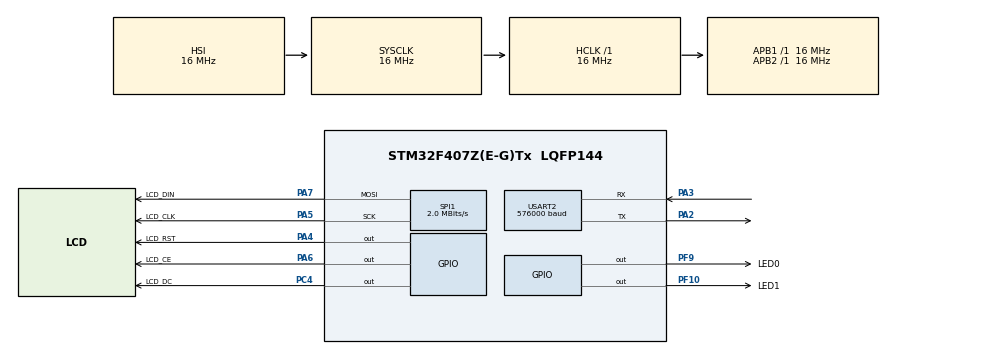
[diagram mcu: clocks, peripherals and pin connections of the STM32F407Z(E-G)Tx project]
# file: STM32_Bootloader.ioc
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Mcu.Family=STM32F4
Mcu.Name=STM32F407Z(E-G)Tx
Mcu.Package=LQFP144
NVIC.PriorityGroup=NVIC_PRIORITYGROUP_4
NVIC.USART2_IRQn=true\:0\:0\:false\:false\:true\:true\:true\:true
PA2.Mode=Asynchronous
PA2.Signal=USART2_TX
PA3.Mode=Asynchronous
PA3.Signal=USART2_RX
PA4.GPIO_Label=LCD_RST
PA4.GPIO_ModeDefaultOutputPP=GPIO_MODE_OUTPUT_PP
PA4.GPIO_PuPd=GPIO_PULLUP
PA4.GPIO_Speed=GPIO_SPEED_FREQ_VERY_HIGH
PA4.PinState=GPIO_PIN_SET
PA4.Signal=GPIO_Output
PA5.GPIO_Label=LCD_CLK
PA5.Mode=TX_Only_Simplex_Unidirect_Master
PA5.Signal=SPI1_SCK
PA6.GPIO_Label=LCD_CE
PA6.GPIO_PuPd=GPIO_PULLUP
PA6.GPIO_Speed=GPIO_SPEED_FREQ_VERY_HIGH
PA6.PinState=GPIO_PIN_SET
PA6.Signal=GPIO_Output
PA7.GPIO_Label=LCD_DIN
PA7.Mode=TX_Only_Simplex_Unidirect_Master
PA7.Signal=SPI1_MOSI
PC4.GPIO_Label=LCD_DC
PC4.GPIO_PuPd=GPIO_PULLUP
PC4.GPIO_Speed=GPIO_SPEED_FREQ_VERY_HIGH
PC4.PinState=GPIO_PIN_SET
PC4.Signal=GPIO_Output
PC6.Signal=SDIO_D6
PF10.GPIO_Label=LED1
PF10.Signal=GPIO_Output
PF9.GPIO_Label=LED0
PF9.Signal=GPIO_Output
ProjectManager.HeapSize=0x200
ProjectManager.StackSize=0x400
ProjectManager.TargetToolchain=STM32CubeIDE
RCC.AHBFreq_Value=16000000
RCC.APB1Freq_Value=16000000
RCC.APB2Freq_Value=16000000
RCC.CortexFreq_Value=16000000
RCC.HSE_VALUE=25000000
RCC.HSI_VALUE=16000000
RCC.LSE_VALUE=32768
RCC.SYSCLKFreq_VALUE=16000000
RCC.VCOOutputFreq_Value=192000000
SPI1.BaudRatePrescaler=SPI_BAUDRATEPRESCALER_8
SPI1.CalculateBaudRate=2.0 MBits/s
SPI1.Direction=SPI_DIRECTION_2LINES
SPI1.Mode=SPI_MODE_MASTER
SPI1.VirtualType=VM_MASTER
USART2.BaudRate=576000
USART2.VirtualMode=VM_ASYNC
board=custom

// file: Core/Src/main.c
/* USER CODE BEGIN Header */
/**
  ******************************************************************************
  * @file           : main.c
  * @brief          : Main program body
  ******************************************************************************
  * @attention
  *
  * Copyright (c) 2024 STMicroelectronics.
  * All rights reserved.
  *
  * This software is licensed under terms that can be found in the LICENSE file
  * in the root directory of this software component.
  * If no LICENSE file comes with this software, it is provided AS-IS.
  *
  ******************************************************************************
  */
/* USER CODE END Header */
#include "main.h"

 SPI_HandleTypeDef hspi1;

UART_HandleTypeDef huart2;

void SystemClock_Config(void);
static void MX_GPIO_Init(void);
static void MX_USART2_UART_Init(void);
static void MX_SPI1_Init(void);
/* USER CODE BEGIN PFP */
extern void initialise_monitor_handles(void);

/* USER CODE END PFP */

int main(void)
{

  /* MCU Configuration--------------------------------------------------------*/

  /* Reset of all peripherals, Initializes the Flash interface and the Systick. */
  HAL_Init();

  /* Configure the system clock */
  SystemClock_Config();

  /* Initialize all configured peripherals */
  MX_GPIO_Init();
  MX_USART2_UART_Init();
  MX_SPI1_Init();
  /* USER CODE BEGIN 2 */

  //initialise_monitor_handles(); // Semi-hosting

  // -- Start LCD Display --
  extern LCD_displayBuffer_t *LCD_displayBuffer01;
  LCD_displayBuffer01 = LCD_SPI_Cmd_initDisplay(LCD_displayBuffer01);

  // -- Start bootloader routine --
  bootloader_init();

  /* USER CODE END 2 */

  /* Infinite loop */
  while (1)
  {

  }
}

void SystemClock_Config(void)
{
  RCC_OscInitTypeDef RCC_OscInitStruct = {0};
  RCC_ClkInitTypeDef RCC_ClkInitStruct = {0};

  /** Configure the main internal regulator output voltage
  */
  __HAL_RCC_PWR_CLK_ENABLE();
  __HAL_PWR_VOLTAGESCALING_CONFIG(PWR_REGULATOR_VOLTAGE_SCALE1);

  /** Initializes the RCC Oscillators according to the specified parameters
  * in the RCC_OscInitTypeDef structure.
  */
  RCC_OscInitStruct.OscillatorType = RCC_OSCILLATORTYPE_HSI;
  RCC_OscInitStruct.HSIState = RCC_HSI_ON;
  RCC_OscInitStruct.HSICalibrationValue = RCC_HSICALIBRATION_DEFAULT;
  RCC_OscInitStruct.PLL.PLLState = RCC_PLL_NONE;
  if (HAL_RCC_OscConfig(&RCC_OscInitStruct) != HAL_OK)
  {
    Error_Handler();
  }

  /** Initializes the CPU, AHB and APB buses clocks
  */
  RCC_ClkInitStruct.ClockType = RCC_CLOCKTYPE_HCLK|RCC_CLOCKTYPE_SYSCLK
                              |RCC_CLOCKTYPE_PCLK1|RCC_CLOCKTYPE_PCLK2;
  RCC_ClkInitStruct.SYSCLKSource = RCC_SYSCLKSOURCE_HSI;
  RCC_ClkInitStruct.AHBCLKDivider = RCC_SYSCLK_DIV1;
  RCC_ClkInitStruct.APB1CLKDivider = RCC_HCLK_DIV1;
  RCC_ClkInitStruct.APB2CLKDivider = RCC_HCLK_DIV1;

  if (HAL_RCC_ClockConfig(&RCC_ClkInitStruct, FLASH_LATENCY_0) != HAL_OK)
  {
    Error_Handler();
  }
}

static void MX_SPI1_Init(void)
{

  /* SPI1 parameter configuration*/
  hspi1.Instance = SPI1;
  hspi1.Init.Mode = SPI_MODE_MASTER;
  hspi1.Init.Direction = SPI_DIRECTION_2LINES;
  hspi1.Init.DataSize = SPI_DATASIZE_8BIT;
  hspi1.Init.CLKPolarity = SPI_POLARITY_LOW;
  hspi1.Init.CLKPhase = SPI_PHASE_1EDGE;
  hspi1.Init.NSS = SPI_NSS_SOFT;
  hspi1.Init.BaudRatePrescaler = SPI_BAUDRATEPRESCALER_8;
  hspi1.Init.FirstBit = SPI_FIRSTBIT_MSB;
  hspi1.Init.TIMode = SPI_TIMODE_DISABLE;
  hspi1.Init.CRCCalculation = SPI_CRCCALCULATION_DISABLE;
  hspi1.Init.CRCPolynomial = 10;
  if (HAL_SPI_Init(&hspi1) != HAL_OK)
  {
    Error_Handler();
  }

}

static void MX_USART2_UART_Init(void)
{

  huart2.Instance = USART2;
  huart2.Init.BaudRate = 576000;
  huart2.Init.WordLength = UART_WORDLENGTH_8B;
  huart2.Init.StopBits = UART_STOPBITS_1;
  huart2.Init.Parity = UART_PARITY_NONE;
  huart2.Init.Mode = UART_MODE_TX_RX;
  huart2.Init.HwFlowCtl = UART_HWCONTROL_NONE;
  huart2.Init.OverSampling = UART_OVERSAMPLING_16;
  if (HAL_UART_Init(&huart2) != HAL_OK)
  {
    Error_Handler();
  }

}

static void MX_GPIO_Init(void)
{
  GPIO_InitTypeDef GPIO_InitStruct = {0};

  /* GPIO Ports Clock Enable */
  __HAL_RCC_GPIOF_CLK_ENABLE();
  __HAL_RCC_GPIOA_CLK_ENABLE();
  __HAL_RCC_GPIOC_CLK_ENABLE();

  /*Configure GPIO pin Output Level */
  HAL_GPIO_WritePin(GPIOF, LED0_Pin|LED1_Pin, GPIO_PIN_RESET);

  /*Configure GPIO pin Output Level */
  HAL_GPIO_WritePin(GPIOA, LCD_RST_Pin|LCD_CE_Pin, GPIO_PIN_SET);

  /*Configure GPIO pin Output Level */
  HAL_GPIO_WritePin(LCD_DC_GPIO_Port, LCD_DC_Pin, GPIO_PIN_SET);

  /*Configure GPIO pins : LED0_Pin LED1_Pin */
  GPIO_InitStruct.Pin = LED0_Pin|LED1_Pin;
  GPIO_InitStruct.Mode = GPIO_MODE_OUTPUT_PP;
  GPIO_InitStruct.Pull = GPIO_NOPULL;
  GPIO_InitStruct.Speed = GPIO_SPEED_FREQ_LOW;
  HAL_GPIO_Init(GPIOF, &GPIO_InitStruct);

  /*Configure GPIO pins : LCD_RST_Pin LCD_CE_Pin */
  GPIO_InitStruct.Pin = LCD_RST_Pin|LCD_CE_Pin;
  GPIO_InitStruct.Mode = GPIO_MODE_OUTPUT_PP;
  GPIO_InitStruct.Pull = GPIO_PULLUP;
  GPIO_InitStruct.Speed = GPIO_SPEED_FREQ_VERY_HIGH;
  HAL_GPIO_Init(GPIOA, &GPIO_InitStruct);

  /*Configure GPIO pin : LCD_DC_Pin */
  GPIO_InitStruct.Pin = LCD_DC_Pin;
  GPIO_InitStruct.Mode = GPIO_MODE_OUTPUT_PP;
  GPIO_InitStruct.Pull = GPIO_PULLUP;
  GPIO_InitStruct.Speed = GPIO_SPEED_FREQ_VERY_HIGH;
  HAL_GPIO_Init(LCD_DC_GPIO_Port, &GPIO_InitStruct);

  /*Configure GPIO pin : PC6 */
  GPIO_InitStruct.Pin = GPIO_PIN_6;
  GPIO_InitStruct.Mode = GPIO_MODE_AF_PP;
  GPIO_InitStruct.Pull = GPIO_NOPULL;
  GPIO_InitStruct.Speed = GPIO_SPEED_FREQ_VERY_HIGH;
  GPIO_InitStruct.Alternate = GPIO_AF12_SDIO;
  HAL_GPIO_Init(GPIOC, &GPIO_InitStruct);

}

/* USER CODE BEGIN 4 */

// ***** Implementation of 'printf' through USART *****
#ifdef __GNUC__
int __io_putchar(int ch)
#else
int fputc(intch, FILE *f)
#endif
{
	HAL_UART_Transmit(&huart2, (uint8_t *)&ch, 1, HAL_MAX_DELAY);
	return ch;
}

/* USER CODE END 4 */

void Error_Handler(void)
{
  __disable_irq();
  while (1)
  {
  }
}
